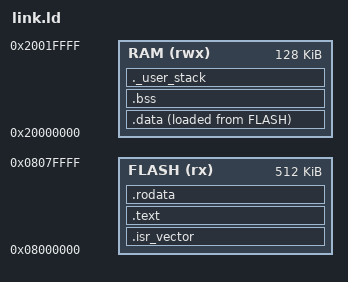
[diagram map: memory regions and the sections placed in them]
/* STM32F411-shaped part: 512 KiB flash, 128 KiB RAM. */
ENTRY(Reset_Handler)

MEMORY
{
  FLASH (rx)  : ORIGIN = 0x08000000, LENGTH = 512K
  RAM   (rwx) : ORIGIN = 0x20000000, LENGTH = 128K
}

_estack = ORIGIN(RAM) + LENGTH(RAM);
_Min_Stack_Size = 0x800;

SECTIONS
{
  .isr_vector :
  {
    . = ALIGN(4);
    KEEP(*(.isr_vector))
    . = ALIGN(4);
  } > FLASH

  .text :
  {
    . = ALIGN(4);
    *(.text)
    *(.text*)
    *(.glue_7)
    *(.glue_7t)
    . = ALIGN(4);
    _etext = .;
  } > FLASH

  .rodata :
  {
    . = ALIGN(4);
    *(.rodata)
    *(.rodata*)
    . = ALIGN(4);
  } > FLASH

  _sidata = LOADADDR(.data);

  .data :
  {
    . = ALIGN(4);
    _sdata = .;
    *(.data)
    *(.data*)
    . = ALIGN(4);
    _edata = .;
  } > RAM AT > FLASH

  .bss (NOLOAD) :
  {
    . = ALIGN(4);
    _sbss = .;
    *(.bss)
    *(.bss*)
    *(COMMON)
    . = ALIGN(4);
    _ebss = .;
  } > RAM

  ._user_stack (NOLOAD) :
  {
    . = ALIGN(8);
    . = . + _Min_Stack_Size;
    . = ALIGN(8);
  } > RAM

  /DISCARD/ :
  {
    libc.a ( * )
    libm.a ( * )
    libgcc.a ( * )
  }

  .ARM.attributes 0 : { *(.ARM.attributes) }
}
